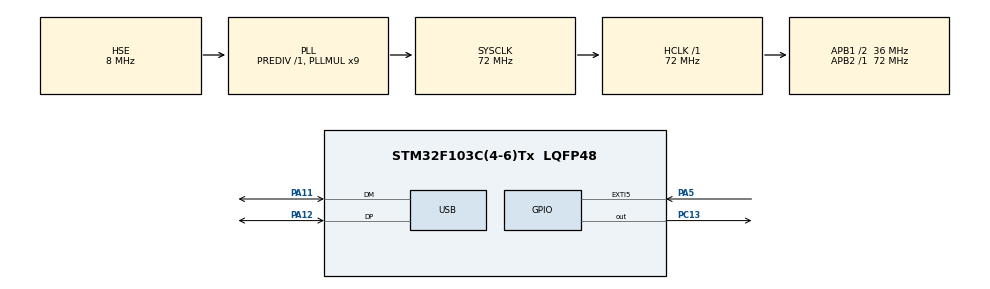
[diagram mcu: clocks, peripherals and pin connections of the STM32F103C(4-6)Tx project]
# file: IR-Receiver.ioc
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Mcu.Family=STM32F1
Mcu.Name=STM32F103C(4-6)Tx
Mcu.Package=LQFP48
NVIC.EXTI9_5_IRQn=true\:0\:0\:false\:false\:true\:true\:true\:true
NVIC.PriorityGroup=NVIC_PRIORITYGROUP_4
NVIC.USB_LP_CAN1_RX0_IRQn=true\:0\:0\:false\:false\:true\:false\:true\:true
PA11.Mode=Device
PA11.Signal=USB_DM
PA12.Mode=Device
PA12.Signal=USB_DP
PA13.Mode=Serial_Wire
PA13.Signal=SYS_JTMS-SWDIO
PA14.Mode=Serial_Wire
PA14.Signal=SYS_JTCK-SWCLK
PA5.GPIO_ModeDefaultEXTI=GPIO_MODE_IT_FALLING
PA5.Signal=GPXTI5
PC13-TAMPER-RTC.Signal=GPIO_Output
PD0-OSC_IN.Mode=HSE-External-Oscillator
PD0-OSC_IN.Signal=RCC_OSC_IN
PD1-OSC_OUT.Mode=HSE-External-Oscillator
PD1-OSC_OUT.Signal=RCC_OSC_OUT
ProjectManager.HeapSize=0x200
ProjectManager.StackSize=0x400
ProjectManager.TargetToolchain=STM32CubeIDE
RCC.AHBFreq_Value=72000000
RCC.APB1CLKDivider=RCC_HCLK_DIV2
RCC.APB1Freq_Value=36000000
RCC.APB1TimFreq_Value=72000000
RCC.APB2Freq_Value=72000000
RCC.APB2TimFreq_Value=72000000
RCC.HCLKFreq_Value=72000000
RCC.PLLMUL=RCC_PLL_MUL9
RCC.SYSCLKFreq_VALUE=72000000
RCC.SYSCLKSource=RCC_SYSCLKSOURCE_PLLCLK
RCC.USBFreq_Value=48000000
RCC.USBPrescaler=RCC_USBCLKSOURCE_PLL_DIV1_5
TIM2.AutoReloadPreload=TIM_AUTORELOAD_PRELOAD_ENABLE
TIM2.Prescaler=71
USB_DEVICE.CLASS_NAME_FS=CDC
USB_DEVICE.VirtualMode=Cdc
USB_DEVICE.VirtualModeFS=Cdc_FS
VP_TIM2_VS_ClockSourceINT.Mode=Internal
VP_USB_DEVICE_VS_USB_DEVICE_CDC_FS.Mode=CDC_FS
board=custom

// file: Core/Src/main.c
/* USER CODE BEGIN Header */
/**
  ******************************************************************************
  * @file           : main.c
  * @brief          : Main program body
  ******************************************************************************
  * @attention
  *
  * Copyright (c) 2025 STMicroelectronics.
  * All rights reserved.
  *
  * This software is licensed under terms that can be found in the LICENSE file
  * in the root directory of this software component.
  * If no LICENSE file comes with this software, it is provided AS-IS.
  *
  ******************************************************************************
  */
/* USER CODE END Header */
#include "main.h"
#include "usb_device.h"
#include "usbd_cdc_if.h"
#include <stdbool.h>

TIM_HandleTypeDef htim2;
volatile uint32_t pulse_timings[100];
volatile uint8_t ir_index = 0;
uint32_t forward =  0x007fac53;
uint32_t backward = 0x007f8976;
uint32_t right =    0x007ff00f;
uint32_t left =     0x007ff10e;
uint32_t stop = 	0x007fb04f;

void SystemClock_Config(void);
static void MX_GPIO_Init(void);
static void MX_TIM2_Init(void);
/* USER CODE BEGIN PFP */
uint32_t decode_nec();
uint32_t process_ir_signal();
void HAL_GPIO_EXTI_Callback(uint16_t GPIO_Pin);
/* USER CODE END PFP */

int main(void)
{

  /* MCU Configuration--------------------------------------------------------*/

  /* Reset of all peripherals, Initializes the Flash interface and the Systick. */
  HAL_Init();

  /* Configure the system clock */
  SystemClock_Config();

  /* Initialize all configured peripherals */
  MX_GPIO_Init();
  MX_TIM2_Init();
  MX_USB_DEVICE_Init();

  /* Infinite loop */
  /* USER CODE BEGIN WHILE */
  HAL_TIM_Base_Start(&htim2);
  uint32_t sig ;
  HAL_GPIO_WritePin(GPIOC, GPIO_PIN_13,1);
  while (1)
  {
    /* USER CODE END WHILE */
	  if(ir_index >= 34){
		  sig = process_ir_signal();
	  }
	  if (sig == forward || sig == right){
	  	HAL_GPIO_WritePin(GPIOC, GPIO_PIN_13,0);
	  }
	  else if (sig == backward || sig == left || sig == stop){
		HAL_GPIO_WritePin(GPIOC, GPIO_PIN_13,1);
	  }
  }
}

void HAL_GPIO_EXTI_Callback(uint16_t GPIO_Pin){
	if (GPIO_Pin == GPIO_PIN_5)  // Assuming PA0
	{
		pulse_timings[ir_index++] = __HAL_TIM_GET_COUNTER(&htim2);
		__HAL_TIM_SET_COUNTER(&htim2, 0);
	}
}

uint32_t decode_nec()
{
  uint32_t result = 0;
  for (uint8_t i = 3; i < 34; i++)
  {
    uint32_t duration = pulse_timings[i];
    result <<= 1;
    if (duration > 1600 && duration < 2400)
      result |= 1;
    else if (duration > 400 && duration < 1200)
      result |= 0;
  }
  return result;
}
uint32_t process_ir_signal()
{
  HAL_NVIC_DisableIRQ(EXTI9_5_IRQn);
  uint32_t code = decode_nec();
  char msg[20] = {0};
  sprintf(msg, "0x%08lX\r\n", code);
  CDC_Transmit_FS((uint8_t *)msg, strlen(msg));

  for(int i = 0 ; i < 34 ; i++){

	  char msg[30] = {0};
	  int x = 2;
	  if (pulse_timings[i] > 1600 && pulse_timings[i] < 2400)
		  x = 1;
	  else if (pulse_timings[i] > 400 && pulse_timings[i] < 1200)
		  x = 0;
	  sprintf(msg, "%d : %d --> %d\r\n",i,(int)pulse_timings[i],x);
	  CDC_Transmit_FS((uint8_t *)msg, strlen(msg));
	  HAL_Delay(10);
	  pulse_timings[i] = 0;
  }
  char separate[]="------------------------------------------------------\r\n";
  CDC_Transmit_FS((uint8_t *)separate, strlen(separate));
  ir_index = 0;
  HAL_NVIC_EnableIRQ(EXTI9_5_IRQn);
  return code ;
}

void SystemClock_Config(void)
{
  RCC_OscInitTypeDef RCC_OscInitStruct = {0};
  RCC_ClkInitTypeDef RCC_ClkInitStruct = {0};
  RCC_PeriphCLKInitTypeDef PeriphClkInit = {0};

  /** Initializes the RCC Oscillators according to the specified parameters
  * in the RCC_OscInitTypeDef structure.
  */
  RCC_OscInitStruct.OscillatorType = RCC_OSCILLATORTYPE_HSE;
  RCC_OscInitStruct.HSEState = RCC_HSE_ON;
  RCC_OscInitStruct.HSEPredivValue = RCC_HSE_PREDIV_DIV1;
  RCC_OscInitStruct.HSIState = RCC_HSI_ON;
  RCC_OscInitStruct.PLL.PLLState = RCC_PLL_ON;
  RCC_OscInitStruct.PLL.PLLSource = RCC_PLLSOURCE_HSE;
  RCC_OscInitStruct.PLL.PLLMUL = RCC_PLL_MUL9;
  if (HAL_RCC_OscConfig(&RCC_OscInitStruct) != HAL_OK)
  {
    Error_Handler();
  }

  /** Initializes the CPU, AHB and APB buses clocks
  */
  RCC_ClkInitStruct.ClockType = RCC_CLOCKTYPE_HCLK|RCC_CLOCKTYPE_SYSCLK
                              |RCC_CLOCKTYPE_PCLK1|RCC_CLOCKTYPE_PCLK2;
  RCC_ClkInitStruct.SYSCLKSource = RCC_SYSCLKSOURCE_PLLCLK;
  RCC_ClkInitStruct.AHBCLKDivider = RCC_SYSCLK_DIV1;
  RCC_ClkInitStruct.APB1CLKDivider = RCC_HCLK_DIV2;
  RCC_ClkInitStruct.APB2CLKDivider = RCC_HCLK_DIV1;

  if (HAL_RCC_ClockConfig(&RCC_ClkInitStruct, FLASH_LATENCY_2) != HAL_OK)
  {
    Error_Handler();
  }
  PeriphClkInit.PeriphClockSelection = RCC_PERIPHCLK_USB;
  PeriphClkInit.UsbClockSelection = RCC_USBCLKSOURCE_PLL_DIV1_5;
  if (HAL_RCCEx_PeriphCLKConfig(&PeriphClkInit) != HAL_OK)
  {
    Error_Handler();
  }
}

static void MX_TIM2_Init(void)
{

  TIM_ClockConfigTypeDef sClockSourceConfig = {0};
  TIM_MasterConfigTypeDef sMasterConfig = {0};

  htim2.Instance = TIM2;
  htim2.Init.Prescaler = 71;
  htim2.Init.CounterMode = TIM_COUNTERMODE_UP;
  htim2.Init.Period = 65535;
  htim2.Init.ClockDivision = TIM_CLOCKDIVISION_DIV1;
  htim2.Init.AutoReloadPreload = TIM_AUTORELOAD_PRELOAD_ENABLE;
  if (HAL_TIM_Base_Init(&htim2) != HAL_OK)
  {
    Error_Handler();
  }
  sClockSourceConfig.ClockSource = TIM_CLOCKSOURCE_INTERNAL;
  if (HAL_TIM_ConfigClockSource(&htim2, &sClockSourceConfig) != HAL_OK)
  {
    Error_Handler();
  }
  sMasterConfig.MasterOutputTrigger = TIM_TRGO_RESET;
  sMasterConfig.MasterSlaveMode = TIM_MASTERSLAVEMODE_DISABLE;
  if (HAL_TIMEx_MasterConfigSynchronization(&htim2, &sMasterConfig) != HAL_OK)
  {
    Error_Handler();
  }

}

static void MX_GPIO_Init(void)
{
  GPIO_InitTypeDef GPIO_InitStruct = {0};

  /* GPIO Ports Clock Enable */
  __HAL_RCC_GPIOC_CLK_ENABLE();
  __HAL_RCC_GPIOD_CLK_ENABLE();
  __HAL_RCC_GPIOA_CLK_ENABLE();

  /*Configure GPIO pin Output Level */
  HAL_GPIO_WritePin(GPIOC, GPIO_PIN_13, GPIO_PIN_RESET);

  /*Configure GPIO pin : PC13 */
  GPIO_InitStruct.Pin = GPIO_PIN_13;
  GPIO_InitStruct.Mode = GPIO_MODE_OUTPUT_PP;
  GPIO_InitStruct.Pull = GPIO_NOPULL;
  GPIO_InitStruct.Speed = GPIO_SPEED_FREQ_LOW;
  HAL_GPIO_Init(GPIOC, &GPIO_InitStruct);

  /*Configure GPIO pin : PA5 */
  GPIO_InitStruct.Pin = GPIO_PIN_5;
  GPIO_InitStruct.Mode = GPIO_MODE_IT_FALLING;
  GPIO_InitStruct.Pull = GPIO_NOPULL;
  HAL_GPIO_Init(GPIOA, &GPIO_InitStruct);

  /* EXTI interrupt init*/
  HAL_NVIC_SetPriority(EXTI9_5_IRQn, 0, 0);
  HAL_NVIC_EnableIRQ(EXTI9_5_IRQn);

}

void Error_Handler(void)
{
  __disable_irq();
  while (1)
  {
  }
}
